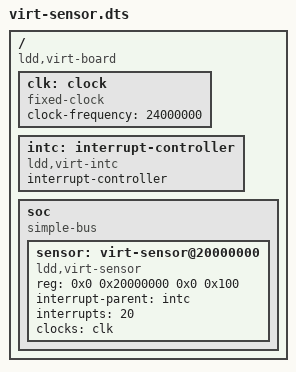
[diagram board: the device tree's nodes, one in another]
/dts-v1/;

/*
 * 真实 SoC 上，probe 会同时看到 reg、interrupts 和 clocks。
 * 客户机没有 CONFIG_OF，virt_sensor.c 在代码里完成同样的三件事。
 */

/ {
	compatible = "ldd,virt-board";
	#address-cells = <2>;
	#size-cells = <2>;

	clk: clock {
		compatible = "fixed-clock";
		#clock-cells = <0>;
		clock-frequency = <24000000>;
	};

	intc: interrupt-controller {
		compatible = "ldd,virt-intc";
		interrupt-controller;
		#interrupt-cells = <1>;
	};

	soc {
		compatible = "simple-bus";
		#address-cells = <2>;
		#size-cells = <2>;
		ranges;

		sensor: virt-sensor@20000000 {
			compatible = "ldd,virt-sensor";
			reg = <0x0 0x20000000 0x0 0x100>;
			interrupt-parent = <&intc>;
			interrupts = <20>;
			clocks = <&clk>;
			clock-names = "sensor";
		};
	};
};
